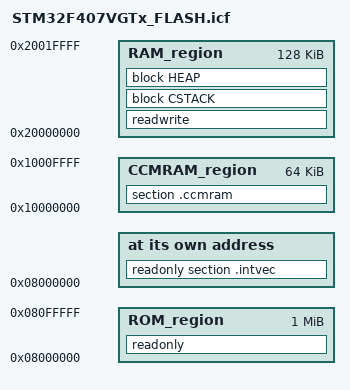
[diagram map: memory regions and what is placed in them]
/*###ICF### Section handled by ICF editor, don't touch! ****/
/*-Editor annotation file-*/
/* IcfEditorFile="$TOOLKIT_DIR$\config\ide\IcfEditor\cortex_v1_0.xml" */
/*-Specials-*/

/**
 * STM32F407VGTx IAR Linker Configuration File
 *
 * Memory Configuration:
 *   - FLASH: 1MB (0x08000000 - 0x080FFFFF)
 *   - SRAM:  192KB (128KB + 64KB CCM)
 *     - Main SRAM: 128KB (0x20000000 - 0x2001FFFF)
 *     - CCM RAM:   64KB  (0x10000000 - 0x1000FFFF)
 *
 * Requirements: 11.4, 12.8
 */

/*-Memory Regions-*/
define symbol __ICFEDIT_intvec_start__ = 0x08000000;

define symbol __ICFEDIT_region_ROM_start__    = 0x08000000;
define symbol __ICFEDIT_region_ROM_end__      = 0x080FFFFF;  /* 1MB Flash */

define symbol __ICFEDIT_region_RAM_start__    = 0x20000000;
define symbol __ICFEDIT_region_RAM_end__      = 0x2001FFFF;  /* 128KB SRAM */

define symbol __ICFEDIT_region_CCMRAM_start__ = 0x10000000;
define symbol __ICFEDIT_region_CCMRAM_end__   = 0x1000FFFF;  /* 64KB CCM RAM */

/*-Sizes-*/
define symbol __ICFEDIT_size_cstack__ = 0x1000;  /* 4KB stack */
define symbol __ICFEDIT_size_heap__   = 0x2000;  /* 8KB heap */
/**** End of ICF editor section. ###ICF###*/

/*-Memory Definitions-*/
define memory mem with size = 4G;

define region ROM_region    = mem:[from __ICFEDIT_region_ROM_start__    to __ICFEDIT_region_ROM_end__];
define region RAM_region    = mem:[from __ICFEDIT_region_RAM_start__    to __ICFEDIT_region_RAM_end__];
define region CCMRAM_region = mem:[from __ICFEDIT_region_CCMRAM_start__ to __ICFEDIT_region_CCMRAM_end__];

/*-Stack and Heap-*/
define block CSTACK with alignment = 8, size = __ICFEDIT_size_cstack__ { };
define block HEAP   with alignment = 8, size = __ICFEDIT_size_heap__   { };

/*-Initialization-*/
initialize by copy { readwrite };
do not initialize  { section .noinit };

/*-Placement-*/
/* Interrupt vector table at start of flash */
place at address mem:__ICFEDIT_intvec_start__ { readonly section .intvec };

/* Read-only sections in ROM */
place in ROM_region { readonly };

/* Read-write sections in RAM */
place in RAM_region { readwrite,
                      block CSTACK,
                      block HEAP };

/* CCM RAM for performance-critical data */
place in CCMRAM_region { section .ccmram };

/*-Exports-*/
/* Export symbols for startup code */
export symbol __ICFEDIT_region_RAM_start__;
export symbol __ICFEDIT_region_RAM_end__;
export symbol __ICFEDIT_size_cstack__;
export symbol __ICFEDIT_size_heap__;
